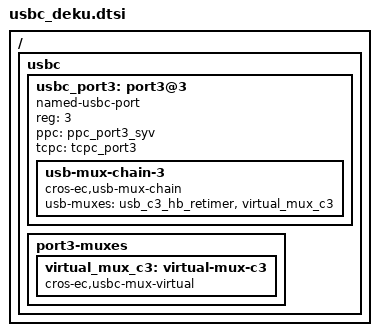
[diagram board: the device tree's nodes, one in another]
/* Copyright 2023 The ChromiumOS Authors
 * Use of this source code is governed by a BSD-style license that can be
 * found in the LICENSE file.
 */

/ {
	usbc {
		#address-cells = <1>;
		#size-cells = <0>;

		usbc_port3: port3@3 {
			compatible = "named-usbc-port";
			reg = <3>;
			ppc = <&ppc_port3_syv>;
			tcpc = <&tcpc_port3>;
			usb-mux-chain-3 {
				compatible = "cros-ec,usb-mux-chain";
				usb-muxes = <&usb_c3_hb_retimer
					     &virtual_mux_c3>;
			};
		};
		port3-muxes {
			virtual_mux_c3: virtual-mux-c3 {
				compatible = "cros-ec,usbc-mux-virtual";
			};
		};
	};
};
